VERSION ""

NS_ :

BS_:

BU_: UserApplication MCM

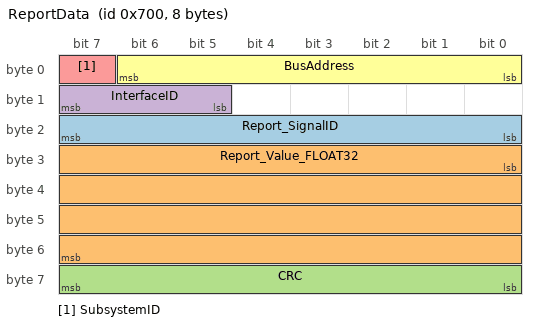
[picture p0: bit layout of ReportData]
BO_ 1792 ReportData: 8 Vector__XXX
 SG_ Report_SignalID M : 16|8@1+ (1,0) [0|0] "" Vector__XXX
 SG_ Report_Value_FLOAT32 : 24|32@1- (1,0) [0|0] "" Vector__XXX
 SG_ CRC : 56|8@1+ (1,0) [0|0] "" Vector__XXX
 SG_ InterfaceID : 13|3@1+ (1,0) [0|0] "" Vector__XXX
 SG_ SubsystemID : 7|1@1+ (1,0) [0|0] "" Vector__XXX
 SG_ BusAddress : 0|7@1+ (1,0) [0|0] "" Vector__XXX

BA_DEF_ SG_  "SigType" ENUM  "Default","Range","RangeSigned","ASCII","Discrete","Control","ReferencePGN","DTC","StringDelimiter","StringLength","StringLengthControl","MessageCounter","MessageChecksum";
BA_DEF_ SG_  "GenSigEVName" STRING ;
BA_DEF_ SG_  "GenSigILSupport" ENUM  "No","Yes";
BA_DEF_ SG_  "GenSigSendType" ENUM  "Cyclic","OnWrite","OnWriteWithRepetition","OnChange","OnChangeWithRepetition","IfActive","IfActiveWithRepetition","NoSigSendType";
BA_DEF_ BO_  "GenMsgILSupport" ENUM  "No","Yes";
BA_DEF_ BU_  "NmStationAddress" INT 0 255;
BA_DEF_ BO_  "GenMsgSendType" ENUM  "cyclic","NotUsed","IfActive","NotUsed","NotUsed","NotUsed","NotUsed","NotUsed","noMsgSendType";
BA_DEF_ BO_  "GenMsgRequestable" INT 0 1;
BA_DEF_  "DBName" STRING ;
BA_DEF_  "BusType" STRING ;
BA_DEF_  "ProtocolType" STRING ;
BA_DEF_ BO_  "VFrameFormat" ENUM  "StandardCAN","ExtendedCAN","reserved","J1939PG";
BA_DEF_DEF_  "SigType" "Default";
BA_DEF_DEF_  "GenSigEVName" "Env@Nodename_@Signame";
BA_DEF_DEF_  "GenSigILSupport" "Yes";
BA_DEF_DEF_  "GenSigSendType" "NoSigSendType";
BA_DEF_DEF_  "GenMsgILSupport" "Yes";
BA_DEF_DEF_  "NmStationAddress" 254;
BA_DEF_DEF_  "GenMsgSendType" "noMsgSendType";
BA_DEF_DEF_  "GenMsgRequestable" 1;
BA_DEF_DEF_  "DBName" "";
BA_DEF_DEF_  "BusType" "CAN";
BA_DEF_DEF_  "ProtocolType" "J1939";
BA_DEF_DEF_  "VFrameFormat" "J1939PG";
BA_ "DBName" "Sygnal";
BA_ "NmStationAddress" BU_ UserApplication 241;
BA_ "NmStationAddress" BU_ MCM 0;
BA_ "VFrameFormat" BO_ 1792 0;
VAL_ 1792 Report_SignalID 116 "Wheel Speed Avg" 115 "Wheel Speed 3" 114 "Wheel Speed 2" 113 "Wheel Speed 1" 112 "Wheel Speed 0" 85 "Closed Loop FB Deriv" 84 "Closed Loop Int Setpoint" 137 "Signal Out Duty Cycle" 136 "Signal In Duty Cycle" 135 "Signal Out Period" 134 "Signal In Period" 133 "Signal Match" 132 "Signal Output State" 131 "Signal Target" 130 "Signal Out DAC" 129 "Signal Out" 128 "Signal In" 83 "Closed Loop Control Out" 82 "Closed Loop Setpoint" 81 "Closed Loop Feedback Norm" 80 "Closed Loop Feedback Raw" 65 "Override Filter Out" 64 "Override State" ;
SIG_VALTYPE_ 1792 Report_Value_FLOAT32 : 1;
